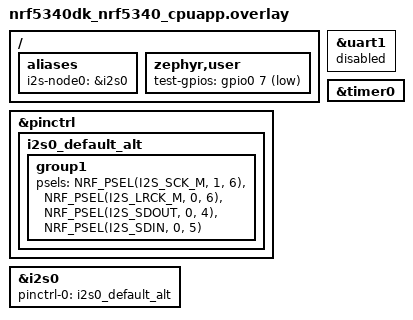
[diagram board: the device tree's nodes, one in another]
/*
 * Copyright (c) 2025 Nordic Semiconductor ASA
 *
 * SPDX-License-Identifier: LicenseRef-Nordic-5-Clause
 */

/* Test requires wire connection:
 *  - I2S_LRCK_M with test-gpios -> P0.06 - P0.07.
 */

/ {
	aliases {
		i2s-node0 = &i2s0;
	};
};

/ {
	zephyr,user {
		test-gpios = <&gpio0 7 GPIO_ACTIVE_LOW>;
	};
};

&pinctrl {
	i2s0_default_alt: i2s0_default_alt {
		group1 {
			psels = <NRF_PSEL(I2S_SCK_M, 1, 6)>,
				<NRF_PSEL(I2S_LRCK_M, 0, 6)>,
				<NRF_PSEL(I2S_SDOUT, 0, 4)>,
				<NRF_PSEL(I2S_SDIN, 0, 5)>;
		};
	};
};

&uart1 {
	status = "disabled";
};

&i2s0 {
	status = "okay";
	pinctrl-0 = <&i2s0_default_alt>;
	pinctrl-names = "default";
};

&timer0 {
	status = "okay";
};
